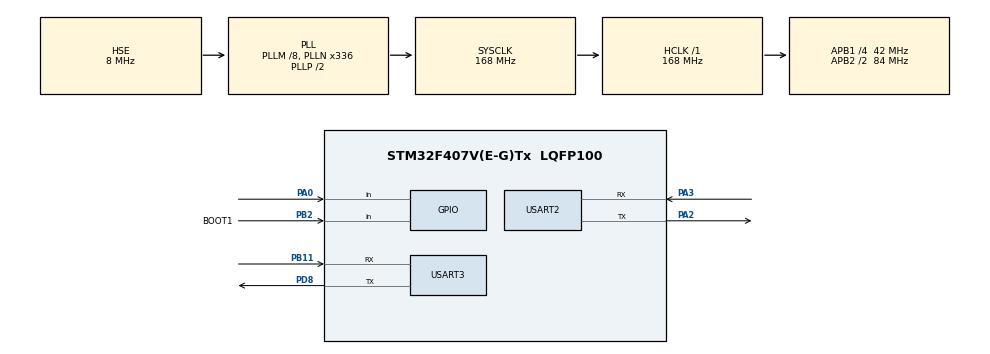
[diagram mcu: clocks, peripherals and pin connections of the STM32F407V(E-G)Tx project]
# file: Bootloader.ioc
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Mcu.Family=STM32F4
Mcu.Name=STM32F407V(E-G)Tx
Mcu.Package=LQFP100
NVIC.PriorityGroup=NVIC_PRIORITYGROUP_0
PA0-WKUP.Signal=GPIO_Input
PA13.GPIO_Label=SWDIO
PA13.Mode=Serial_Wire
PA13.Signal=SYS_JTMS-SWDIO
PA14.GPIO_Label=SWCLK
PA14.Mode=Serial_Wire
PA14.Signal=SYS_JTCK-SWCLK
PA2.Mode=Asynchronous
PA2.Signal=USART2_TX
PA3.Mode=Asynchronous
PA3.Signal=USART2_RX
PB11.Mode=Asynchronous
PB11.Signal=USART3_RX
PB2.GPIO_Label=BOOT1
PB2.GPIO_Mode=GPIO_MODE_INPUT
PB2.GPIO_PuPd=GPIO_NOPULL
PB2.Signal=GPIO_Input
PB3.GPIO_Label=SWO
PB3.Signal=SYS_JTDO-SWO
PC14-OSC32_IN.GPIO_Label=PC14-OSC32_IN
PC14-OSC32_IN.Mode=LSE-External-Oscillator
PC14-OSC32_IN.Signal=RCC_OSC32_IN
PC15-OSC32_OUT.GPIO_Label=PC15-OSC32_OUT
PC15-OSC32_OUT.Mode=LSE-External-Oscillator
PC15-OSC32_OUT.Signal=RCC_OSC32_OUT
PD8.Mode=Asynchronous
PD8.Signal=USART3_TX
PH0-OSC_IN.GPIO_Label=PH0-OSC_IN
PH0-OSC_IN.Mode=HSE-External-Oscillator
PH0-OSC_IN.Signal=RCC_OSC_IN
PH1-OSC_OUT.GPIO_Label=PH1-OSC_OUT
PH1-OSC_OUT.Mode=HSE-External-Oscillator
PH1-OSC_OUT.Signal=RCC_OSC_OUT
ProjectManager.HeapSize=0x200
ProjectManager.StackSize=0x400
ProjectManager.TargetToolchain=STM32CubeIDE
RCC.48MHZClocksFreq_Value=48000000
RCC.AHBFreq_Value=168000000
RCC.APB1CLKDivider=RCC_HCLK_DIV4
RCC.APB1Freq_Value=42000000
RCC.APB1TimFreq_Value=84000000
RCC.APB2CLKDivider=RCC_HCLK_DIV2
RCC.APB2Freq_Value=84000000
RCC.APB2TimFreq_Value=168000000
RCC.CortexFreq_Value=168000000
RCC.HCLKFreq_Value=168000000
RCC.HSE_VALUE=8000000
RCC.HSI_VALUE=16000000
RCC.PLLM=8
RCC.PLLN=336
RCC.PLLQ=7
RCC.PLLSourceVirtual=RCC_PLLSOURCE_HSE
RCC.SYSCLKFreq_VALUE=168000000
RCC.SYSCLKSource=RCC_SYSCLKSOURCE_PLLCLK
RCC.VCOOutputFreq_Value=336000000
USART2.VirtualMode=VM_ASYNC
USART3.VirtualMode=VM_ASYNC
board=STM32F407G-DISC1

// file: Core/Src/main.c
/* USER CODE BEGIN Header */
/**
  ******************************************************************************
  * @file           : main.c
  * @brief          : Main program body
  ******************************************************************************
  * @attention
  *
  * Copyright (c) 2023 STMicroelectronics.
  * All rights reserved.
  *
  * This software is licensed under terms that can be found in the LICENSE file
  * in the root directory of this software component.
  * If no LICENSE file comes with this software, it is provided AS-IS.
  *
  ******************************************************************************
  */
/* USER CODE END Header */
#include "main.h"

/* USER CODE BEGIN Includes */
#include <stdio.h>
#include "etx_ota_update.h"
/* USER CODE END Includes */

/* USER CODE BEGIN PM */
#define MAJOR 0   // BL Major version Number
#define MINOR 2   // BL Minor version Number
/* USER CODE END PM */

UART_HandleTypeDef huart2;
UART_HandleTypeDef huart3;

/* USER CODE BEGIN PV */
const uint8_t BL_Version[2] = { MAJOR, MINOR };
/* USER CODE END PV */

void SystemClock_Config(void);
static void MX_GPIO_Init(void);
static void MX_USART2_UART_Init(void);
static void MX_USART3_UART_Init(void);
/* USER CODE BEGIN PFP */
static void goto_application( void );
/* USER CODE END PFP */

int main(void)
{

  /* MCU Configuration--------------------------------------------------------*/

  /* Reset of all peripherals, Initializes the Flash interface and the Systick. */
  HAL_Init();

  /* Configure the system clock */
  SystemClock_Config();

  /* Initialize all configured peripherals */
  MX_GPIO_Init();
  MX_USART2_UART_Init();
  MX_USART3_UART_Init();
  /* USER CODE BEGIN 2 */
  // Turn ON the Green Led to tell the user that Bootloader is running
  HAL_GPIO_WritePin(GPIOD, GPIO_PIN_12, GPIO_PIN_SET );    //Green LED ON
  printf("Starting Bootloader(%d.%d)\r\n", BL_Version[0], BL_Version[1] );
  //HAL_Delay(2000);   //2sec delay for nothing

  /* Check the GPIO for 3 seconds */
  GPIO_PinState OTA_Pin_state;
  uint32_t end_tick = HAL_GetTick() + 3000;   // from now to 3 Seconds
  printf("Press the User Button PC13 to trigger OTA update...\r\n");
    do
    {
      OTA_Pin_state = HAL_GPIO_ReadPin( GPIOA, GPIO_PIN_0 );
      uint32_t current_tick = HAL_GetTick();

      /* Check the button is pressed or not for 3seconds */
      if( ( OTA_Pin_state != GPIO_PIN_RESET ) || ( current_tick > end_tick ) )
      {
        /* Either timeout or Button is pressed */
        break;
      }
    }while( 1 );

    /*Start the Firmware or Application update */
    if( OTA_Pin_state == GPIO_PIN_SET )
    {
      printf("Starting Firmware Download!!!\r\n");
      HAL_GPIO_WritePin(GPIOD, GPIO_PIN_12, GPIO_PIN_RESET );    //Green LED ON
      /* OTA Request. Receive the data from the UART4 and flash */
      if( etx_ota_download_and_flash() != ETX_OTA_EX_OK )
      {
        /* Error. Don't process. */
        printf("OTA Update : ERROR!!! HALT!!!\r\n");
        while( 1 );
      }
      else
      {
        /* Reset to load the new application */
        printf("Firmware update is done!!! Rebooting...\r\n");
        HAL_NVIC_SystemReset();
      }
    }

    // Jump to application
    goto_application();
  /* USER CODE END 2 */

  /* Infinite loop */
  while (1)
  {

  }
}

void SystemClock_Config(void)
{
  RCC_OscInitTypeDef RCC_OscInitStruct = {0};
  RCC_ClkInitTypeDef RCC_ClkInitStruct = {0};

  /** Configure the main internal regulator output voltage
  */
  __HAL_RCC_PWR_CLK_ENABLE();
  __HAL_PWR_VOLTAGESCALING_CONFIG(PWR_REGULATOR_VOLTAGE_SCALE1);

  /** Initializes the RCC Oscillators according to the specified parameters
  * in the RCC_OscInitTypeDef structure.
  */
  RCC_OscInitStruct.OscillatorType = RCC_OSCILLATORTYPE_HSE;
  RCC_OscInitStruct.HSEState = RCC_HSE_ON;
  RCC_OscInitStruct.PLL.PLLState = RCC_PLL_ON;
  RCC_OscInitStruct.PLL.PLLSource = RCC_PLLSOURCE_HSE;
  RCC_OscInitStruct.PLL.PLLM = 8;
  RCC_OscInitStruct.PLL.PLLN = 336;
  RCC_OscInitStruct.PLL.PLLP = RCC_PLLP_DIV2;
  RCC_OscInitStruct.PLL.PLLQ = 7;
  if (HAL_RCC_OscConfig(&RCC_OscInitStruct) != HAL_OK)
  {
    Error_Handler();
  }

  /** Initializes the CPU, AHB and APB buses clocks
  */
  RCC_ClkInitStruct.ClockType = RCC_CLOCKTYPE_HCLK|RCC_CLOCKTYPE_SYSCLK
                              |RCC_CLOCKTYPE_PCLK1|RCC_CLOCKTYPE_PCLK2;
  RCC_ClkInitStruct.SYSCLKSource = RCC_SYSCLKSOURCE_PLLCLK;
  RCC_ClkInitStruct.AHBCLKDivider = RCC_SYSCLK_DIV1;
  RCC_ClkInitStruct.APB1CLKDivider = RCC_HCLK_DIV4;
  RCC_ClkInitStruct.APB2CLKDivider = RCC_HCLK_DIV2;

  if (HAL_RCC_ClockConfig(&RCC_ClkInitStruct, FLASH_LATENCY_5) != HAL_OK)
  {
    Error_Handler();
  }
}

static void MX_USART2_UART_Init(void)
{

  huart2.Instance = USART2;
  huart2.Init.BaudRate = 115200;
  huart2.Init.WordLength = UART_WORDLENGTH_8B;
  huart2.Init.StopBits = UART_STOPBITS_1;
  huart2.Init.Parity = UART_PARITY_NONE;
  huart2.Init.Mode = UART_MODE_TX_RX;
  huart2.Init.HwFlowCtl = UART_HWCONTROL_NONE;
  huart2.Init.OverSampling = UART_OVERSAMPLING_16;
  if (HAL_UART_Init(&huart2) != HAL_OK)
  {
    Error_Handler();
  }

}

static void MX_USART3_UART_Init(void)
{

  huart3.Instance = USART3;
  huart3.Init.BaudRate = 115200;
  huart3.Init.WordLength = UART_WORDLENGTH_8B;
  huart3.Init.StopBits = UART_STOPBITS_1;
  huart3.Init.Parity = UART_PARITY_NONE;
  huart3.Init.Mode = UART_MODE_TX_RX;
  huart3.Init.HwFlowCtl = UART_HWCONTROL_NONE;
  huart3.Init.OverSampling = UART_OVERSAMPLING_16;
  if (HAL_UART_Init(&huart3) != HAL_OK)
  {
    Error_Handler();
  }

}

static void MX_GPIO_Init(void)
{
  GPIO_InitTypeDef GPIO_InitStruct = {0};

  /* GPIO Ports Clock Enable */
  __HAL_RCC_GPIOC_CLK_ENABLE();
  __HAL_RCC_GPIOH_CLK_ENABLE();
  __HAL_RCC_GPIOA_CLK_ENABLE();
  __HAL_RCC_GPIOB_CLK_ENABLE();
  __HAL_RCC_GPIOD_CLK_ENABLE();

  /*Configure GPIO pin : PA0 */
  GPIO_InitStruct.Pin = GPIO_PIN_0;
  GPIO_InitStruct.Mode = GPIO_MODE_INPUT;
  GPIO_InitStruct.Pull = GPIO_NOPULL;
  HAL_GPIO_Init(GPIOA, &GPIO_InitStruct);

  /*Configure GPIO pin : BOOT1_Pin */
  GPIO_InitStruct.Pin = BOOT1_Pin;
  GPIO_InitStruct.Mode = GPIO_MODE_INPUT;
  GPIO_InitStruct.Pull = GPIO_NOPULL;
  HAL_GPIO_Init(BOOT1_GPIO_Port, &GPIO_InitStruct);
  /*Configure GPIO pin : BOOT1_Pin */
	GPIO_InitStruct.Pin = GPIO_PIN_12;
	GPIO_InitStruct.Mode = GPIO_MODE_OUTPUT_PP;
	GPIO_InitStruct.Pull = GPIO_NOPULL;
	HAL_GPIO_Init(GPIOD, &GPIO_InitStruct);

}

/* USER CODE BEGIN 4 */
/**
  * @brief Print the characters to UART (printf).
  * @retval int
  */
#ifdef __GNUC__
  /* With GCC, small printf (option LD Linker->Libraries->Small printf
     set to 'Yes') calls __io_putchar() */
int __io_putchar(int ch)
#else
int fputc(int ch, FILE *f)
#endif /* __GNUC__ */
{
  /* Place your implementation of fputc here */
  /* e.g. write a character to the UART3 and Loop until the end of transmission */
  HAL_UART_Transmit(&huart3, (uint8_t *)&ch, 1, HAL_MAX_DELAY);

  return ch;
}

/**
  * @brief Jump to application from the Bootloader
  * @retval None
  */
static void goto_application(void)
{
  printf("Gonna Jump to Application\r\n");

  void (*app_reset_handler)(void) = (void*)(*((volatile uint32_t*) (0x08040000 + 4U)));

  //__set_MSP(*(volatile uint32_t*) 0x08040000);

  // Turn OFF the Green Led to tell the user that Bootloader is not running
  HAL_GPIO_WritePin(GPIOB, GPIO_PIN_0, GPIO_PIN_RESET );    //Green LED OFF
  app_reset_handler();    //call the app reset handler
}
/* USER CODE END 4 */

void Error_Handler(void)
{
  __disable_irq();
  while (1)
  {
  }
}
